# pmac_rx_secure register map
Vendor: Texas Instruments
Peripheral module from a debugger description file (folder CC35X1E).
Registers are 32-bit, read-only, reset 0x0 unless marked. A register's access mark holds for its fields unless they carry their own. Offsets are as the file gives them; lines under a group give offsets from that group; [hi:lo] are bit positions; {n}, {i} and the like mark numbered series; 'fields as' and 'values as' point back to an identical list; <NAME> marks a mode.

## pmac_rx_secure (part 1 of 3)
0x00 rx_reset access per field — Receive Reset (RX_RESET) Register
  [0] MEM_RXM_RESET rw — Receive Reset (rxm_reset) When set this bit puts the Receive Manager in reset.
0x04 sta_ssid0 rw — Station SSID Registers (STA_SSID0)
  [31:0] MEM_STA_SSID_031_000 — Station SSID bytes 3..0
0x08 sta_ssid1 rw — Station SSID Registers (STA_SSID1)
  [31:0] MEM_STA_SSID_063_032 — Station SSID bytes 7..4
0x0C sta_ssid2 rw — Station SSID Registers (STA_SSID2)
  [31:0] MEM_STA_SSID_095_064 — Station SSID bytes 11..8
0x10 sta_ssid3 rw — Station SSID Registers (STA_SSID3)
  [31:0] MEM_STA_SSID_127_096 — Station SSID bytes 15..12
0x14 sta_ssid4 rw — Station SSID Registers (STA_SSID4)
  [31:0] MEM_STA_SSID_159_128 — Station SSID bytes 23..20
0x18 sta_ssid5 rw — Station SSID Registers (STA_SSID5)
  [31:0] MEM_STA_SSID_191_160 — Station SSID bytes 23..20
0x1C sta_ssid6 rw — Station SSID Registers (STA_SSID6)
  [31:0] MEM_STA_SSID_223_192 — Station SSID bytes 27..24
0x20 sta_ssid7 rw — Station SSID Registers (STA_SSID7)
  [31:0] MEM_STA_SSID_255_224 — Station SSID bytes 31..28
0x24 ssid_len access per field — Station SSID Length (SSID_LEN)
  [5:0] MEM_SSID_LENGTH rw — Station SSID length in bytes. The number of valid bytes in STA_SSID0..7 to be used for comparison.
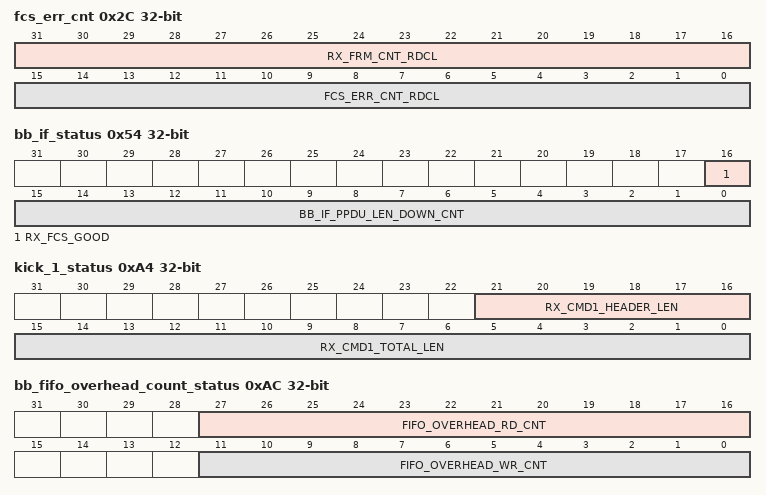
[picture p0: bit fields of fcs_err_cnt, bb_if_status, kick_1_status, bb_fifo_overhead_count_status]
0x2C fcs_err_cnt — Rx Frame count and FCS ERROR count
  [31:16] RX_FRM_CNT_RDCL — Counts number of MPDU_s received. does not count PLCP header errors clears on read
  [15:0] FCS_ERR_CNT_RDCL — Count of FCS errors detected by the Receive Manager. clears on read
0x30 rx_scrpt_tmp_mask access per field reset not defined
  [7:0] RX_SCRPT_TMP_MASK_IN_WROPT rw — used by the scripter on single address commands.
0x34 rx_scrpt_tmp_val access per field reset not defined
  [7:0] RX_SCRPT_TMP_VALUE_IN_WROPT rw — used by the scripter on specific commands and on if/jump commands
0x38 rx_scrpt_tmp_lnk access per field reset not defined
  [8:0] RX_SCRPT_TMP_LINK_IN_WROPT rw — used by the LINK command as the return address.
0x40 phy_hdr_word0
  [31:0] PHY_HEADER_WORD0 — [31:16] - Length [15:8] - Rate [7] - Aggregation (at 11n) [6] - Guard Interval (at 11n/11ac) 0x0: 0.4us (SGI) 0x1: 0.8us (LGI) [5:4] - BW (at 11n/ac/ax) [3:0] - Packet and Preamble type: 0x0: 11b short preamble 0x1: 11b long preamble 0x2: 11a/g (legacy OFDM) 0x3: 11n HT MF 0x4: 11ax SU 0x5: 11ax MU 0x6: 11ax SU ER 0x7: 11ax TB 0x8: 11ax TB non NDP 0x9: 11ac VHT 0xA-0xF: Reserved
0x44 phy_hdr_word1
  [31:0] PHY_HEADER_WORD1 — [31] - Reserved [30] - TXOP[6] (at 11ax) [29:24] - Group ID (at 11ac) / TXOP[5:0] (at 11ax) [23] - Reserved [22] - HT/VHT/HE error packet [21] - Legacy error packet [20:16] - Unsupported packet 0x0: Supported packet 0x1: LDPC coding 0x2: STBC 0x3: Rate 0x4: BW=40MHz 0x5: BW=80MHz 0x6: BW=160MHz 0x7: Greenfield preamble 0x8: MIMO 0x9: TB AX 0xA: VHT MU 0xB: HE Doppler 0xC: Other 0xD-0x1F: Reserved [15:14] - Reserved [13:8] - SNR [7:0] - RSSI
0x48 phy_hdr_word2
  [31:0] PHY_HEADER_WORD2 — [31:29] - GI & HE LTF Type (at 11ax) [28:16] - RX Time [15] - Uplink flag (at 11ax) [14:11] - Spacial reuse[3:0] (at 11ax) [10:9] - STA_ID_LIST[2:1] (at 11ax) [8] - Partial_AID[8] (at 11ac) / STA_ID_LIST[0] (at 11ax) [7:0] - Partial_AID[7:0] (at 11ac) / RU allocation (at 11ax)
0x4C phy_hdr_word3
  [31:0] PHY_HEADER_WORD3 — [31:16] - Reserved [15] - Beamformed [14] - DCM [13:8] - BSS color [7:0] - HE RSSI (at 11ax)
0x50 phy_mac_byte_cnt
  [19:0] PHY_MAC_BYTE_CNT — Register that monitors the number of bytes coming from the phy for each PPDU. Counter increments with "rxif_data_stb" and resets to "1" on "rxif_begin_stb"
0x54 bb_if_status
  [16] RX_FCS_GOOD — Indicates whether a received frame had a valid FCS
  [15:0] BB_IF_PPDU_LEN_DOWN_CNT — BB_IF PPDU Length down counter
{0x54+4i} mac_header_word{i} (i=1..9) — Receive MAC Header Registers (MAC_HEADER_WORD{i})
{0x54+4i} mac_header_word{i} (i=10..13) — Receive MAC Header Registers (MAC_HEADER_WORD9)
0x90 mac_header_bytecnt — Receive MAC Header Byte Count (MAC_HEADER_BYTECNT) Register
  [15:0] MAC_HEADER_BYTECNT — MAC Header Byte Count (mac_header_bytecnt). Number of valid bytes in the RX MAC HEADER registers.
0x94 fcs_word — Receive MAC Header Byte Count (MAC_HEADER_BYTECNT) Register
  [31:0] FCS_WORD — FCS word received from PHY
0xA0 rx_manager_ovrhd_word
  [31:0] RX_MNG_1ST_OVERHEAD_WORD — 1st overhead word that rx-manager reads from bb-fifo [15:0] = Frame Control [31:16] = MPDU-Length
0xA4 kick_1_status — status of last cmd1 (kick_1) from Rx-Manager to ENC (DMA)
  [21:16] RX_CMD1_HEADER_LEN — kick_1 MAC header length in bytes
  [15:0] RX_CMD1_TOTAL_LEN — kick_1 total_len in bytes without FCS
0xA8 mpdu_len_status
  [15:0] MPDU_LENGTH_BB_IF — MPDU length from BB_IF fifo input (including 4 bytes FCS) at first, when plcp rx_header received: loaded with PPDU_LENGTH in case of aggregation (AMPDU): loaded with MPDU_LEN from each head-delimiter
0xAC bb_fifo_overhead_count_status
  [27:16] FIFO_OVERHEAD_RD_CNT — number of overhead words read from bb-fifo (cleared at rx-header)
  [11:0] FIFO_OVERHEAD_WR_CNT — number of overhead words written to bb-fifo (cleared at rx-header)
0xB0 he_cfg access per field reset 0xFFF — Configuration for HE format
  [5:0] MEM_CFG_BSS_COLOR rw — Configurable 'BSS_COLOR' of this device.
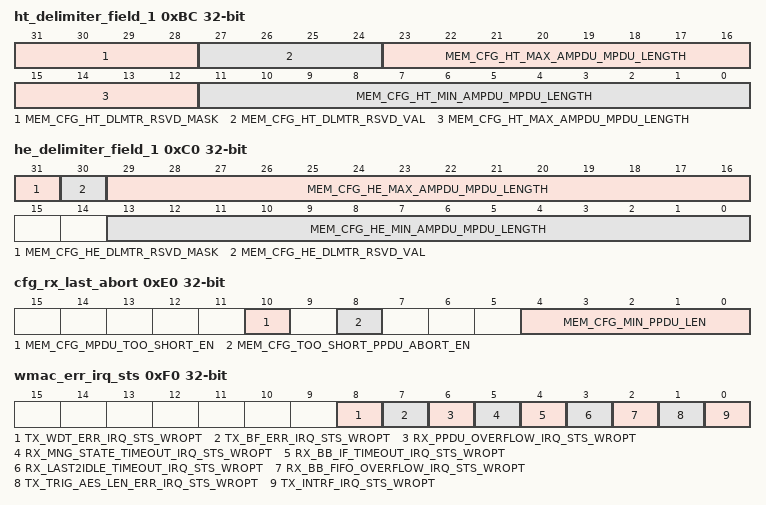
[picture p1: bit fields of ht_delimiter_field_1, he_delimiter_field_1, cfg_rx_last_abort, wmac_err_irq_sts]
0xBC ht_delimiter_field_1 rw reset not defined — contrls the configuration options of the AMPDU parsing for HT AMPDU 19xx name changed
  [31:28] MEM_CFG_HT_DLMTR_RSVD_MASK — 1 means that the related bit in delimiter reserved value field is not compared.
  [27:24] MEM_CFG_HT_DLMTR_RSVD_VAL — The reserved field of the delimiter is compared with this value (check mask feild below)
  [23:12] MEM_CFG_HT_MAX_AMPDU_MPDU_LENGTH — A delimiter with length bigger then the value in this feild is filterred.
  [11:0] MEM_CFG_HT_MIN_AMPDU_MPDU_LENGTH — A delimiter with length smaller then the value in this feild is filterred. min value is 14 = 10 (shortest MAC header) + 4 (FCS)
0xC0 he_delimiter_field_1 access per field reset not defined — contrls the configuration options of the AMPDU parsing for HE AMPDU
  [31] MEM_CFG_HE_DLMTR_RSVD_MASK rw — 1 means that the related bit in delimiter reserved value field is not compared.
  [30] MEM_CFG_HE_DLMTR_RSVD_VAL rw — The reserved field of the delimiter is compared with this value (check mask field below)
  [29:16] MEM_CFG_HE_MAX_AMPDU_MPDU_LENGTH rw — A delimiter with length bigger then the value in this feild is filterred.
  [13:0] MEM_CFG_HE_MIN_AMPDU_MPDU_LENGTH rw — A delimiter with length smaller then the value in this feild is filterred. min value is 14 = 10 (shortest MAC header) + 4 (FCS)
0xCC mac_abort access per field — Abort mac frame
  [0] MAC_ABORT_SW_CMD_WRCL wo — Create a pulse to abort current received frame
0xD0 cfg_abort_interrupt_mask access per field — Controls maskin the interrupts on RX path due to PPDU ABORT.
  [4:0] MEM_CFG_ABORT_INTERRUPT_MASK rw — [0] = cfg_mask_phy_termination [1] = cfg_mask_header_abort [2] = cfg_mask_suspend_req_to_phy [3] = cfg_mask_too_short_ppdu_abort [4] = cfg_mask_mac_abort
0xD4 abort_status access per field — This registers contains the status of the ppdu abort interrupt. The F/W should write 0 to clear this register bits.
  [4:0] PPDU_ABORT_STATUS_WROPT rw — [0] = phy_termination [1] = header_abort [2] = Abort due to suspend [3] = too_short_ppdu_abort [4] = mac_abort
0xD8 rx_spare_reg0 rw — spare register for future use
  [31:0] MEM_RX_SPARE_REG0
0xDC rx_spare_reg1 rw reset 0xFFFFFFFF — spare register for future use
  [31:0] MEM_RX_SPARE_REG1
0xE0 cfg_rx_last_abort access per field reset not defined — enable delay_last_abort feature which provied a last abort only after all but the aborted MPDU were analized thus preventing previous MPDUs from being aborted without a reason. WL9 new
  [10] MEM_CFG_MPDU_TOO_SHORT_EN rw — 1 - will set the byte_cnt to 63 to free scripter in case the mpdu is shorter than its mac header length and the scripter looks for a missing data 0 - feature disabled
  [8] MEM_CFG_TOO_SHORT_PPDU_ABORT_EN rw — 1- enable too_short_ppdu_abort i.e. ppdus less than a configured length that are not NDP will be aborted 0 - no abort on too short ppdu
  [4:0] MEM_CFG_MIN_PPDU_LEN rw — when cfg_too_short_ppdu_abort_en - a received ppdu with length under this number will be aborted
0xE4 cfg_ndp_fcs access per field reset 0x3 — enable setting fcs_ok for NDP packets to avoid EIFS timer start counting for NDP
  [0] MEM_CFG_NDP_IS_FCS_OK rw — "1" - NDP packets receiving outomatically sets the fcs_ok avoiding the EIFS timers from counting "0" - NDP packets are treated as having BAD FCS thus starting the EIFS timers counting.
0xF0 wmac_err_irq_sts access per field — pmac error indication status. This register allow clear - writing 1 will clear a source. Selective clear should be done with read-modify-write
  [8] TX_WDT_ERR_IRQ_STS_WROPT rw — unmasked irq status TX watchdog expiry.
  [7] TX_BF_ERR_IRQ_STS_WROPT rw — unmasked irq status. Beamforming NDPA was received with invalid parameters.
  [6] RX_PPDU_OVERFLOW_IRQ_STS_WROPT rw — unmasked irq status new PPDU received while previous not completed by rx-manager. PPDU processing is time is represented by RIP (rx in progress) set by rising of rx_header and cleared by rx_frm_stb which is rx_manager goes to IDLE after finished processing PPDU. PPDU_OVERFLOW is set if new rx_header is received while RIP is high
  [5] RX_MNG_STATE_TIMEOUT_IRQ_STS_WROPT rw — unmasked irq status rx_manager state (other than IDLE) is not changed for too long time time [msec] is defined in rx register MEM_RX_MNG_STATE_TIMEOUT_MSEC helps to identify if FSM is stuck
  [4] RX_BB_IF_TIMEOUT_IRQ_STS_WROPT rw — unmasked irq status RX BB I/F - no data received from phy for too long time checked from rx_header rise to rx_last time [usec] is defined in rx register MEM_BB_IF_TIMEOUT_USEC[5:0] helps to identify if MAC-PHY interface is stuck
  [3] RX_LAST2IDLE_TIMEOUT_IRQ_STS_WROPT rw — unmasked irq status IRQ generated if time elapsed from RX_LAST to RX_FRM_STB (manager-go-to-idle) is equal or above threshold. threshold is defined by rx-reg MEM_RX_STATISTICS_LAST2IDLE_THR[9:0] count in clock cycles (20MHz, 50ns) NOTE: part of RX_STATISTICS module, need to set mem_rx_statistics_en=1
  [2] RX_BB_FIFO_OVERFLOW_IRQ_STS_WROPT rw — unmasked irq status PHY try to write new data to RX BB FIFO while it is full (new data is lost)
  [1] TX_TRIG_AES_LEN_ERR_IRQ_STS_WROPT rw — unmasked irq status
  [0] TX_INTRF_IRQ_STS_WROPT rw — unmasked irq status
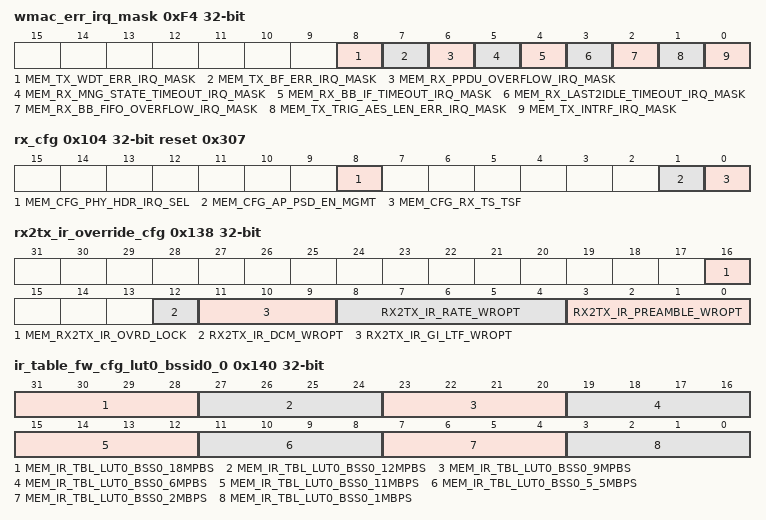
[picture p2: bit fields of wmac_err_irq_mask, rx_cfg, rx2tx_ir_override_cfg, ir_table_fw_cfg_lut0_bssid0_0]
0xF4 wmac_err_irq_mask access per field
  [8] MEM_TX_WDT_ERR_IRQ_MASK rw — when set, current source wont interrupt the SW. status will still be updated.
  [7] MEM_TX_BF_ERR_IRQ_MASK rw — when set, current source wont interrupt the SW. status will still be updated.
  [6] MEM_RX_PPDU_OVERFLOW_IRQ_MASK rw — when set, current source wont interrupt the SW. status will still be updated.
  [5] MEM_RX_MNG_STATE_TIMEOUT_IRQ_MASK rw — when set, current source wont interrupt the SW. status will still be updated.
  [4] MEM_RX_BB_IF_TIMEOUT_IRQ_MASK rw — when set, current source wont interrupt the SW. status will still be updated.
  [3] MEM_RX_LAST2IDLE_TIMEOUT_IRQ_MASK rw — when set, current source wont interrupt the SW. status will still be updated.
  [2] MEM_RX_BB_FIFO_OVERFLOW_IRQ_MASK rw — when set, current source wont interrupt the SW. status will still be updated.
  [1] MEM_TX_TRIG_AES_LEN_ERR_IRQ_MASK rw — when set, current source wont interrupt the SW. status will still be updated.
  [0] MEM_TX_INTRF_IRQ_MASK rw — when set, current source wont interrupt the SW. status will still be updated.
0x100 rx_timestamp — Receive Time Stamp (RX_TIMESTAMP)
  [31:0] RX_MAC_TIMESTAMP — Sample of timestamp counter (free running or TSF. see RX_CFG bit 0) on rx_header_stb
0x104 rx_cfg access per field reset 0x307 — HT managment is enabled
  [8] MEM_CFG_PHY_HDR_IRQ_SEL rw — Select location of phy-header interrupt: 0 - (default) at the end of phy_header (header fall) 1 - at the begining of phy_header (header rise)
  [1] MEM_CFG_AP_PSD_EN_MGMT rw — include management frame types when checking if a connected STA changed PS state. 1 - include mgmg 0 - only data frames.
  [0] MEM_CFG_RX_TS_TSF rw — Hardware Receive timestamp select (RX_TIMESTAMP); 0 = sample realtime free running microsecond counter; 1 = sample Access Manager TSF
0x10C cfg_ht_mgmt_en access per field reset 0x3 — HT managment is enabled
  [0] MEM_CFG_ENABLE_HT_MGMT rw — enable HT managment is enabled
0x138 rx2tx_ir_override_cfg access per field reset not defined
  [16] MEM_RX2TX_IR_OVRD_LOCK rw — Lock Override operation on rx2tx_ir_* outputs: 0 - Disable (Default) - Outputs override are valid only to this current frame, and will be released at the next frame start (phy_hdr_start_stb). 1 - Enable - When override (using this reg) - Output values are permanently lock for next frames, and can't be changed through HW.
  [12] RX2TX_IR_DCM_WROPT rw — 0 - DCM is not used (Default) 1 - Dual Carrier Modulation is used Note: DCM is only applied to MCS0, MCS1, MCS3 and MCS4
  [11:9] RX2TX_IR_GI_LTF_WROPT rw — In case og 11n/11ac: 0 - 0.4uS (SGI) 1 - 0.8uS (LGI) (Default) 2-7 - RESERVED ------------------------------- In case of 11ax: 0x0: 1xLTF+1.6us GI 0x1: 2xLTF+1.6us GI 0x2: 4xLTF+3.2us GI 0x3: 2xLTF+0.8us GI 0x4: 1xLTF+0.8us GI 0x5: 4xLTF+0.8us GI 0x6-0x7 - RESERVED
  [8:4] RX2TX_IR_RATE_WROPT rw — 5'h1 - 11B 1MBPS 5'h2 - 11B 2MBPS 5'h3 - 11B 5.5MBPS 5'h4 - 11B 11MBPS 5'h5 - 11AG 6MBPS (Default) 5'h6 - 11AG 9MBPS 5'h7 - 11AG 12MBPS 5'h8 - 11AG 18MBPS 5'h9 - 11AG 24MBPS 5'hA - 11AG 36MBPS 5'hB - 11AG 48MBPS 5'hC - 11AG 54MBPS 5'hD - 11N MCS0 //6.5 Mbps 5'hE - 11N MCS1 //13 Mbps 5'hF - 11N MCS2 //19.5 Mbps 5'h10 - 11N MCS3 //26 Mbps 5'h11 - 11N MCS4 //39 Mbps 5'h12 - 11N MCS5 //52 Mbps 5'h13 - 11N MCS6 //58.5 Mbps 5'h14 - 11N MCS7 //65 Mbps 5'h15 - 11N MCS7_SGI //72.2 Mbps
  [3:0] RX2TX_IR_PREAMBLE_WROPT rw — 0x0: 11b short preamble 0x1: 11b long preamble 0x2: 11a/g (legacy OFDM) (Default) 0x3: 11n HT Mixed-Mode 0x4: 11n GF 0x5: 11ax SU 0x6: 11ax MU 0x7: 11ax SU ER 0x8: 11ax TB (non NDP FB) 0x9: 11ax TB NDP TB 0xA: 11ac VHT 0xB: 11ax Unknown Type 0xC-0xF: Reserved
0x140 ir_table_fw_cfg_lut0_bssid0_0 rw — LUT0 - BSSID0 - for Legacy frame response. Configuration of the basic rate set of the BSSID (as published by the AP). Used to select the response rate for each input rate (legacy or translated-MCS rate to the closest legacy rate). * DANGEROUS - set with caution: * If you config response with 11B rate-1, and we receive 11B Short preamble, * we trigger imm-resp with INCOMPATIBLE params
  [31:28] MEM_IR_TBL_LUT0_BSS0_18MPBS — Configured RATE of the response frame for 18Mbps input rate (11a/g).
  [27:24] MEM_IR_TBL_LUT0_BSS0_12MPBS — Configured RATE of the response frame for 12Mbps input rate (11a/g).
  [23:20] MEM_IR_TBL_LUT0_BSS0_9MPBS — Configured RATE of the response frame for 9Mbps input rate (11a/g).
  [19:16] MEM_IR_TBL_LUT0_BSS0_6MPBS — Configured RATE of the response frame for 6Mbps input rate (11a/g).
  [15:12] MEM_IR_TBL_LUT0_BSS0_11MBPS — Configured RATE of the response frame for 11Mbps input rate (11b).
  [11:8] MEM_IR_TBL_LUT0_BSS0_5_5MBPS — Configured RATE of the response frame for 5.5Mbps input rate (11b).
  [7:4] MEM_IR_TBL_LUT0_BSS0_2MBPS — Configured RATE of the response frame for 2Mbps input rate (11b).
  [3:0] MEM_IR_TBL_LUT0_BSS0_1MBPS — Configured RATE of the response frame for 1Mbps input rate (11b).
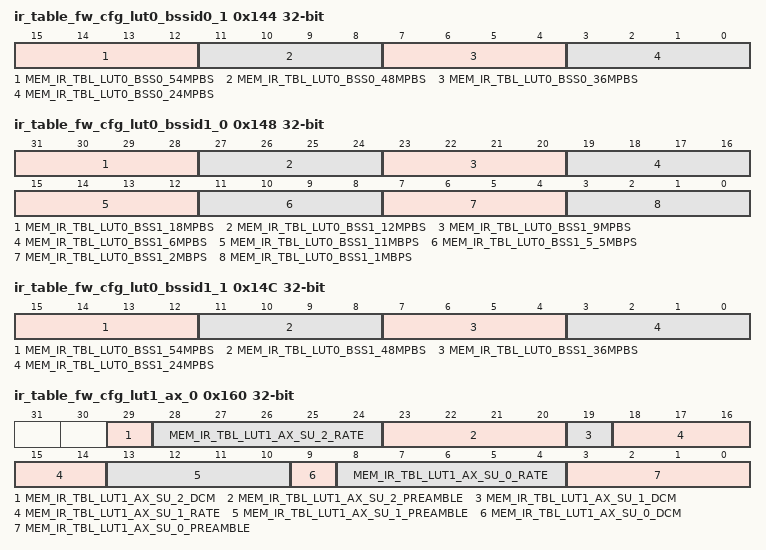
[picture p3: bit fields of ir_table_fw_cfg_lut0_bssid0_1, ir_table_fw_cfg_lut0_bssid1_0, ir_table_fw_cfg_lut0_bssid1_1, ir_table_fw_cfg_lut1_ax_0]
0x144 ir_table_fw_cfg_lut0_bssid0_1 access per field — LUT0 - BSSID0 - for Legacy frame response. Configuration of the basic rate set of the BSSID (as published by the AP). Used to select the response rate for each input rate (legacy or translated MCS-rate to the closest legacy rate).
  [15:12] MEM_IR_TBL_LUT0_BSS0_54MPBS rw — Configured RATE of the response frame for 54Mbps input rate (11a/g).
  [11:8] MEM_IR_TBL_LUT0_BSS0_48MPBS rw — Configured RATE of the response frame for 48Mbps input rate (11a/g).
  [7:4] MEM_IR_TBL_LUT0_BSS0_36MPBS rw — Configured RATE of the response frame for 36Mbps input rate (11a/g).
  [3:0] MEM_IR_TBL_LUT0_BSS0_24MPBS rw — Configured RATE of the response frame for 24Mbps input rate (11a/g).
0x148 ir_table_fw_cfg_lut0_bssid1_0 rw — LUT0 - BSSID1 - for Legacy frame response. Configuration of the basic rate set of the BSSID (as published by the AP). Used to select the response rate for each input rate (legacy or translated-MCS rate to the closest legacy rate). * DANGEROUS - set with caution: * If you config response with 11B rate-1, and we receive 11B Short preamble, * we trigger imm-resp with INCOMPATIBLE params
  [31:28] MEM_IR_TBL_LUT0_BSS1_18MPBS — Configured RATE of the response frame for 18Mbps input rate (11a/g).
  [27:24] MEM_IR_TBL_LUT0_BSS1_12MPBS — Configured RATE of the response frame for 12Mbps input rate (11a/g).
  [23:20] MEM_IR_TBL_LUT0_BSS1_9MPBS — Configured RATE of the response frame for 9Mbps input rate (11a/g).
  [19:16] MEM_IR_TBL_LUT0_BSS1_6MPBS — Configured RATE of the response frame for 6Mbps input rate (11a/g).
  [15:12] MEM_IR_TBL_LUT0_BSS1_11MBPS — Configured RATE of the response frame for 11Mbps input rate (11b).
  [11:8] MEM_IR_TBL_LUT0_BSS1_5_5MBPS — Configured RATE of the response frame for 5.5Mbps input rate (11b).
  [7:4] MEM_IR_TBL_LUT0_BSS1_2MBPS — Configured RATE of the response frame for 2Mbps input rate (11b).
  [3:0] MEM_IR_TBL_LUT0_BSS1_1MBPS — Configured RATE of the response frame for 1Mbps input rate (11b).
0x14C ir_table_fw_cfg_lut0_bssid1_1 access per field — LUT0 - BSSID1 - for Legacy frame response. Configuration of the basic rate set of the BSSID (as published by the AP). Used to select the response rate for each input rate (legacy or translated MCS-rate to the closest legacy rate).
  [15:12] MEM_IR_TBL_LUT0_BSS1_54MPBS rw — Configured RATE of the response frame for 54Mbps input rate (11a/g).
  [11:8] MEM_IR_TBL_LUT0_BSS1_48MPBS rw — Configured RATE of the response frame for 48Mbps input rate (11a/g).
  [7:4] MEM_IR_TBL_LUT0_BSS1_36MPBS rw — Configured RATE of the response frame for 36Mbps input rate (11a/g).
  [3:0] MEM_IR_TBL_LUT0_BSS1_24MPBS rw — Configured RATE of the response frame for 24Mbps input rate (11a/g).
0x160 ir_table_fw_cfg_lut1_ax_0 access per field — LUT1 - AX - for HE frame response. Configuration for the HE imm-resp Output set (Preamble, Rate, DCM). Param in: AX-SU (MCS0-MCS2)
  [29] MEM_IR_TBL_LUT1_AX_SU_2_DCM rw — Configured DCM mode of the AX response frame for MCS2 (19.5Mbps).
  [28:24] MEM_IR_TBL_LUT1_AX_SU_2_RATE rw — Configured RATE of the AX response frame for MCS2 (19.5Mbps).
  [23:20] MEM_IR_TBL_LUT1_AX_SU_2_PREAMBLE rw — Configured PREAMBLE of the AX response frame for MCS2 (19.5Mbps).
  [19] MEM_IR_TBL_LUT1_AX_SU_1_DCM rw — Configured DCM mode of the AX response frame for MCS1 (13Mbps).
  [18:14] MEM_IR_TBL_LUT1_AX_SU_1_RATE rw — Configured RATE of the AX response frame for MCS1 (13Mbps).
  [13:10] MEM_IR_TBL_LUT1_AX_SU_1_PREAMBLE rw — Configured PREAMBLE of the AX response frame for MCS1 (13Mbps).
  [9] MEM_IR_TBL_LUT1_AX_SU_0_DCM rw — Configured DCM mode of the AX response frame for MCS0 (6.5Mbps).
  [8:4] MEM_IR_TBL_LUT1_AX_SU_0_RATE rw — Configured RATE of the AX response frame for MCS0 (6.5Mbps).
  [3:0] MEM_IR_TBL_LUT1_AX_SU_0_PREAMBLE rw — Configured PREAMBLE of the AX response frame for MCS0 (6.5Mbps).
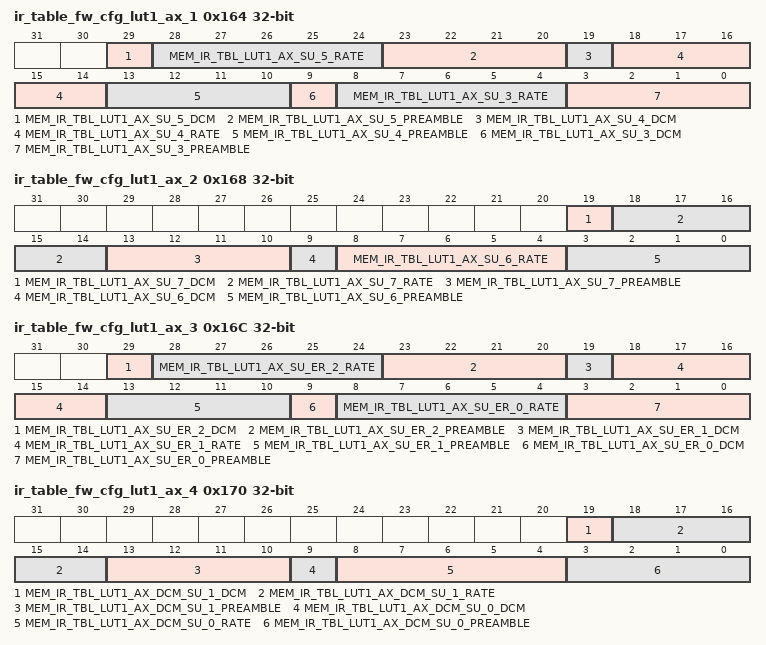
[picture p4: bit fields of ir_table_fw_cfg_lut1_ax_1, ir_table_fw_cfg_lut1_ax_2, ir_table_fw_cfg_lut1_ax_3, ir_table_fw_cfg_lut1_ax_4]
0x164 ir_table_fw_cfg_lut1_ax_1 access per field reset not defined — LUT1 - AX - for HE frame response. Configuration for the HE imm-resp Output set (Preamble, Rate, DCM). Param in: AX-SU (MCS2-MCS5)
  [29] MEM_IR_TBL_LUT1_AX_SU_5_DCM rw — Configured DCM mode of the AX response frame for MCS5 (52Mbps).
  [28:24] MEM_IR_TBL_LUT1_AX_SU_5_RATE rw — Configured RATE of the AX response frame for MCS5 (52Mbps).
  [23:20] MEM_IR_TBL_LUT1_AX_SU_5_PREAMBLE rw — Configured PREAMBLE of the AX response frame for MCS5 (52Mbps).
  [19] MEM_IR_TBL_LUT1_AX_SU_4_DCM rw — Configured DCM mode of the AX response frame for MCS4 (39Mbps).
  [18:14] MEM_IR_TBL_LUT1_AX_SU_4_RATE rw — Configured RATE of the AX response frame for MCS4 (39Mbps).
  [13:10] MEM_IR_TBL_LUT1_AX_SU_4_PREAMBLE rw — Configured PREAMBLE of the AX response frame for MCS4 (39Mbps).
  [9] MEM_IR_TBL_LUT1_AX_SU_3_DCM rw — Configured DCM mode of the AX response frame for MCS3 (26Mbps).
  [8:4] MEM_IR_TBL_LUT1_AX_SU_3_RATE rw — Configured RATE of the AX response frame for MCS3 (26Mbps).
  [3:0] MEM_IR_TBL_LUT1_AX_SU_3_PREAMBLE rw — Configured PREAMBLE of the AX response frame for MCS3 (26Mbps).
0x168 ir_table_fw_cfg_lut1_ax_2 access per field reset not defined — LUT1 - AX - for HE frame response. Configuration for the HE imm-resp Output set (Preamble, Rate, DCM). Param in: AX-SU (MCS6-MCS7)
  [19] MEM_IR_TBL_LUT1_AX_SU_7_DCM rw — Configured DCM mode of the AX response frame for MCS7 (72.2Mbps).
  [18:14] MEM_IR_TBL_LUT1_AX_SU_7_RATE rw — Configured RATE of the AX response frame for MCS7 (72.2Mbps).
  [13:10] MEM_IR_TBL_LUT1_AX_SU_7_PREAMBLE rw — Configured PREAMBLE of the AX response frame for MCS7 (72.2Mbps).
  [9] MEM_IR_TBL_LUT1_AX_SU_6_DCM rw — Configured DCM mode of the AX response frame for MCS6 (58.5Mbps).
  [8:4] MEM_IR_TBL_LUT1_AX_SU_6_RATE rw — Configured RATE of the AX response frame for MCS6 (58.5Mbps).
  [3:0] MEM_IR_TBL_LUT1_AX_SU_6_PREAMBLE rw — Configured PREAMBLE of the AX response frame for MCS6 (58.5Mbps).
0x16C ir_table_fw_cfg_lut1_ax_3 access per field reset not defined — LUT1 - AX - for HE frame response. Configuration for the HE imm-resp Output set (Preamble, Rate, DCM). Param in: AX-SU_ER (MCS0-MCS2)
  [29] MEM_IR_TBL_LUT1_AX_SU_ER_2_DCM rw — Configured DCM mode of the AX response frame for MCS2 (19.5Mbps).
  [28:24] MEM_IR_TBL_LUT1_AX_SU_ER_2_RATE rw — Configured RATE of the AX response frame for MCS2 (19.5Mbps).
  [23:20] MEM_IR_TBL_LUT1_AX_SU_ER_2_PREAMBLE rw — Configured PREAMBLE of the AX response frame for MCS2 (19.5Mbps).
  [19] MEM_IR_TBL_LUT1_AX_SU_ER_1_DCM rw — Configured DCM mode of the AX response frame for MCS1 (13Mbps).
  [18:14] MEM_IR_TBL_LUT1_AX_SU_ER_1_RATE rw — Configured RATE of the AX response frame for MCS1 (13Mbps).
  [13:10] MEM_IR_TBL_LUT1_AX_SU_ER_1_PREAMBLE rw — Configured PREAMBLE of the AX response frame for MCS1 (13Mbps).
  [9] MEM_IR_TBL_LUT1_AX_SU_ER_0_DCM rw — Configured DCM mode of the AX response frame for MCS0 (6.5Mbps).
  [8:4] MEM_IR_TBL_LUT1_AX_SU_ER_0_RATE rw — Configured RATE of the AX response frame for MCS0 (6.5Mbps).
  [3:0] MEM_IR_TBL_LUT1_AX_SU_ER_0_PREAMBLE rw — Configured PREAMBLE of the AX response frame for MCS0 (6.5Mbps).
0x170 ir_table_fw_cfg_lut1_ax_4 access per field reset not defined — LUT1 - AX - for HE frame response. Configuration for the HE imm-resp Output set (Preamble, Rate, DCM). Param in: AX-SU-DCM (MCS0-MCS2)
  [19] MEM_IR_TBL_LUT1_AX_DCM_SU_1_DCM rw — Configured DCM mode of the AX response frame for MCS1 (13Mbps).
  [18:14] MEM_IR_TBL_LUT1_AX_DCM_SU_1_RATE rw — Configured RATE of the AX response frame for MCS1 (13Mbps).
  [13:10] MEM_IR_TBL_LUT1_AX_DCM_SU_1_PREAMBLE rw — Configured PREAMBLE of the AX response frame for MCS1 (13Mbps).
  [9] MEM_IR_TBL_LUT1_AX_DCM_SU_0_DCM rw — Configured DCM mode of the AX response frame for MCS0 (6.5Mbps).
  [8:4] MEM_IR_TBL_LUT1_AX_DCM_SU_0_RATE rw — Configured RATE of the AX response frame for MCS0 (6.5Mbps).
  [3:0] MEM_IR_TBL_LUT1_AX_DCM_SU_0_PREAMBLE rw — Configured PREAMBLE of the AX response frame for MCS0 (6.5Mbps).
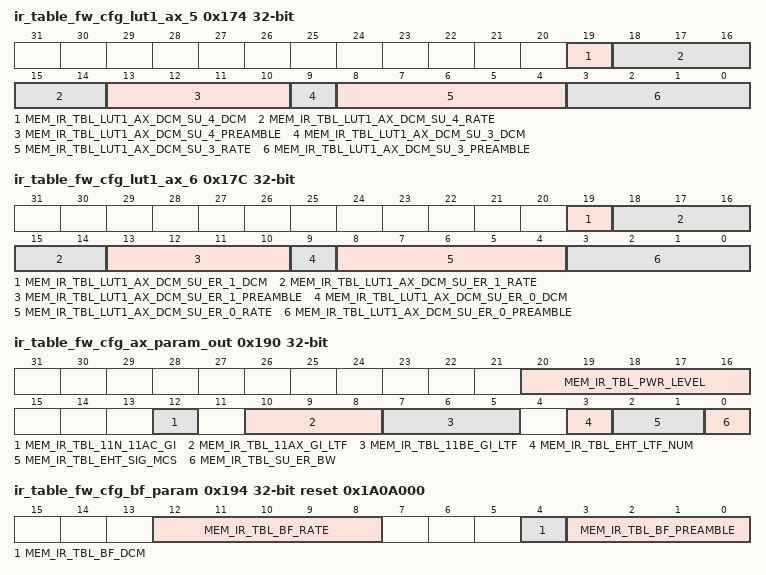
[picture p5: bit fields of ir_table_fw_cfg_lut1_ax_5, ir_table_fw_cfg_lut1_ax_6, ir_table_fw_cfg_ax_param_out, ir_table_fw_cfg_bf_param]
0x174 ir_table_fw_cfg_lut1_ax_5 access per field reset not defined — LUT1 - AX - for HE frame response. Configuration for the HE imm-resp Output set (Preamble, Rate, DCM). Param in: AX-SU-DCM (MCS2-MCS5)
  [19] MEM_IR_TBL_LUT1_AX_DCM_SU_4_DCM rw — Configured DCM mode of the AX response frame for MCS4 (39Mbps).
  [18:14] MEM_IR_TBL_LUT1_AX_DCM_SU_4_RATE rw — Configured RATE of the AX response frame for MCS4 (39Mbps).
  [13:10] MEM_IR_TBL_LUT1_AX_DCM_SU_4_PREAMBLE rw — Configured PREAMBLE of the AX response frame for MCS4 (39Mbps).
  [9] MEM_IR_TBL_LUT1_AX_DCM_SU_3_DCM rw — Configured DCM mode of the AX response frame for MCS3 (26Mbps).
  [8:4] MEM_IR_TBL_LUT1_AX_DCM_SU_3_RATE rw — Configured RATE of the AX response frame for MCS3 (26Mbps).
  [3:0] MEM_IR_TBL_LUT1_AX_DCM_SU_3_PREAMBLE rw — Configured PREAMBLE of the AX response frame for MCS3 (26Mbps).
0x17C ir_table_fw_cfg_lut1_ax_6 access per field reset not defined — LUT1 - AX - for HE frame response. Configuration for the HE imm-resp Output set (Preamble, Rate, DCM). Param in: AX-SU_ER-DCM (MCS0-MCS2)
  [19] MEM_IR_TBL_LUT1_AX_DCM_SU_ER_1_DCM rw — Configured DCM mode of the AX response frame for MCS1 (13Mbps).
  [18:14] MEM_IR_TBL_LUT1_AX_DCM_SU_ER_1_RATE rw — Configured RATE of the AX response frame for MCS1 (13Mbps).
  [13:10] MEM_IR_TBL_LUT1_AX_DCM_SU_ER_1_PREAMBLE rw — Configured PREAMBLE of the AX response frame for MCS1 (13Mbps).
  [9] MEM_IR_TBL_LUT1_AX_DCM_SU_ER_0_DCM rw — Configured DCM mode of the AX response frame for MCS0 (6.5Mbps).
  [8:4] MEM_IR_TBL_LUT1_AX_DCM_SU_ER_0_RATE rw — Configured RATE of the AX response frame for MCS0 (6.5Mbps).
  [3:0] MEM_IR_TBL_LUT1_AX_DCM_SU_ER_0_PREAMBLE rw — Configured PREAMBLE of the AX response frame for MCS0 (6.5Mbps).
0x190 ir_table_fw_cfg_ax_param_out access per field reset not defined — AX parameters - for HE frame response. Configuration for the HE imm-resp Output set: SU_ER_BW, GI_LTF PWR_LEVEL.
  [20:16] MEM_IR_TBL_PWR_LEVEL rw — Power Level selection for imm response. (Statically configuration - Not related to the frame params in) Configured HE single user (SU), HE extended range (ER) of the AX response frame. (Statically configuration - Not related to the frame params in)
  [12] MEM_IR_TBL_11N_11AC_GI rw — Configured GI subfield of the 11N/11AC response frame. (Statically configuration - Not related to the frame params in) 0 - 0.4uS (SGI) 1 - 0.8uS (LGI) (Default)
  [10:8] MEM_IR_TBL_11AX_GI_LTF rw — Configured GI and LTF Type subfield of the AX response frame. (Statically configuration - Not related to the frame params in) 0x0: 1xLTF+1.6us GI 0x1: 2xLTF+1.6us GI 0x2: 4xLTF+3.2us GI (Default) 0x3: 2xLTF+0.8us GI 0x4: 1xLTF+0.8us GI 0x5: 4xLTF+0.8us GI 0x6-0x7 - RESERVED
  [7:5] MEM_IR_TBL_11BE_GI_LTF rw — Configured GI and LTF Type subfield of the BE response frame. (Statically configuration - Not related to the frame params in) 0x0: 1xLTF+1.6us GI 0x1: 2xLTF+1.6us GI 0x2: 4xLTF+3.2us GI (Default) 0x3: 2xLTF+0.8us GI 0x4: 1xLTF+0.8us GI 0x5: 4xLTF+0.8us GI 0x6-0x7 - RESERVED
  [3] MEM_IR_TBL_EHT_LTF_NUM rw — Configured HE single user (SU), HE extended range (ER) of the AX response frame. (Statically configuration - Not related to the frame params in)
  [2:1] MEM_IR_TBL_EHT_SIG_MCS rw — Configured HE single user (SU), HE extended range (ER) of the AX response frame. (Statically configuration - Not related to the frame params in)
  [0] MEM_IR_TBL_SU_ER_BW rw — Configured HE single user (SU), HE extended range (ER) of the AX response frame. (Statically configuration - Not related to the frame params in)
0x194 ir_table_fw_cfg_bf_param access per field reset 0x1A0A000 (reset mask 0xFFFFE000) — Dedicated parameters - for BeamForming frame. Configuration Output set: PREAMBLE RATE
  [12:8] MEM_IR_TBL_BF_RATE rw — Configured RATE for BeamForming frame transmission.
  [4] MEM_IR_TBL_BF_DCM rw — Configured DCM for BeamForming frame transmission.
  [3:0] MEM_IR_TBL_BF_PREAMBLE rw — Configured PREAMBLE for BeamForming frame transmission.
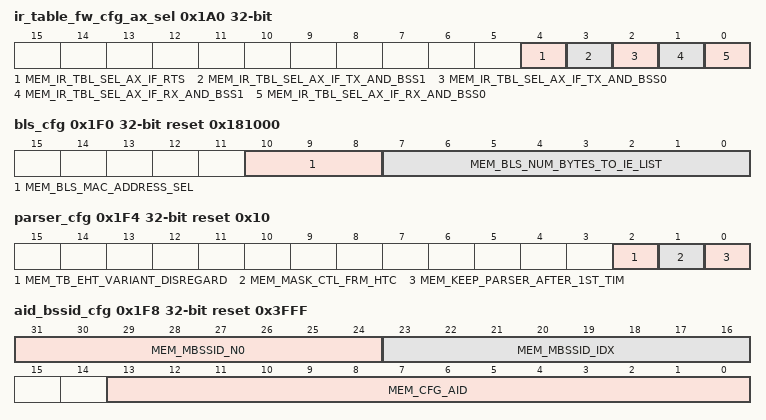
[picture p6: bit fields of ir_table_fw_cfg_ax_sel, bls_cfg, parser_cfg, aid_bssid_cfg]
0x1A0 ir_table_fw_cfg_ax_sel access per field — Configuration bits for the decision of selecting AX Table (LUT1) over the Legacy one (LUT0)
  [4] MEM_IR_TBL_SEL_AX_IF_RTS rw — Select AX Table if: Frame Type: Control-RTS
  [3] MEM_IR_TBL_SEL_AX_IF_TX_AND_BSS1 rw — Select AX Table if: 1. Client = PMAC-TX 2. BSSID Role Index = 1
  [2] MEM_IR_TBL_SEL_AX_IF_TX_AND_BSS0 rw — Select AX Table if: 1. Client = PMAC-TX 2. BSSID Role Index = 0
  [1] MEM_IR_TBL_SEL_AX_IF_RX_AND_BSS1 rw — Select AX Table if: 1. Client = PMAC-RX 2. BSSID Role Index = 1
  [0] MEM_IR_TBL_SEL_AX_IF_RX_AND_BSS0 rw — Select AX Table if: 1. Client = PMAC-RX 2. BSSID Role Index = 0
0x1F0 bls_cfg access per field reset 0x181000 (reset mask 0xFFFFF800) — BLS feature configuration
  [10:8] MEM_BLS_MAC_ADDRESS_SEL rw — Select one of the 6 configurable MAC-Addresses (ADDR_SRCH_ADDR_*) to the fake SA (address 2) of the BLS frame. This way it gets valid link/role/bssid matches and indexs
  [7:0] MEM_BLS_NUM_BYTES_TO_IE_LIST rw — Configuration of the number of bytes, after the sync pattern, and before start of new IE. Constrains on this value: * Must be >=2 (since it is used also as 'hdr_len', so can't be 0) * In range of [2..24] must be even number, otherwise any value
0x1F4 parser_cfg access per field reset 0x10 (reset mask 0xFFFFFFF8)
  [2] MEM_TB_EHT_VARIANT_DISREGARD rw — When set, parser will treat all tb frames as HE regardless of actual format
  [1] MEM_MASK_CTL_FRM_HTC rw — Mask HTC bit (frame control bit-15) in case AP uses it as reserved and sends control frame with 'HTC=1' and without HT-Control field.
  [0] MEM_KEEP_PARSER_AFTER_1ST_TIM rw — In case there are several TIM-Elements in a frame: 0 - (default) - stop searching for Broadcast/Unicast indication after 1st TIM. 1 - keep searching and parsing till the end of packet.
0x1F8 aid_bssid_cfg access per field reset 0x3FFF (reset mask 0x3FFF) — Association ID Register + Multi BSSID configuration
  [31:24] MEM_MBSSID_N0 rw — For Single-BSSID (n=0): Set N0 to 0. For Multi-BSSID: For n={1,2,3,4,5,6,7...} - N0 should be set to {1,1,1,2,4,8,16...} respectively. (n - is an integer power of 2, where n^2 is the maximum possible number of BSSID; and N0 is the smallest positive integer such that: N0 x 8 - 2^n < 8) In case of Multi BSSID mode, this register value (=N0) helps to extract the traffic indication bit of the associated station from the virtual bitmap of the TIM element: If Bitmap Offset = 0, N0 is don't care and traffic indication virtual bitmap is extracted according to method A, (BBSID's broadcast indication is according to mbssid_idx reg). If Bitmap Offset > 0, Using it + N0 to find AID_min in the virtual bitmap - according to Method B.
  [23:16] MEM_MBSSID_IDX rw — This register value is the index of actually supported BSSID, where the corresponding bit in the vbm indicates on broadcast frames that are buffered at the AP for this BSS: In case of multi BSSID mode: 'mbssid_idx' can be in range of [0:k] (where k<=(2^n - 1), 'mbssid_idx'=0 corresponds to the transmitted BSSID, and 'mssid_idx'>0 to one of the non-transmitted BSSID). In case of single BSSID mode: This register value is don't-care.
  [13:0] MEM_CFG_AID rw — AID of station
{0x1F8+8i} parser_rx_addr_{i}_lsb (i=1..4)
  [31:0] RX_ADDR{i}_31_00 — Note: bits [7:0] are actually ADDR MSB = first byte from air
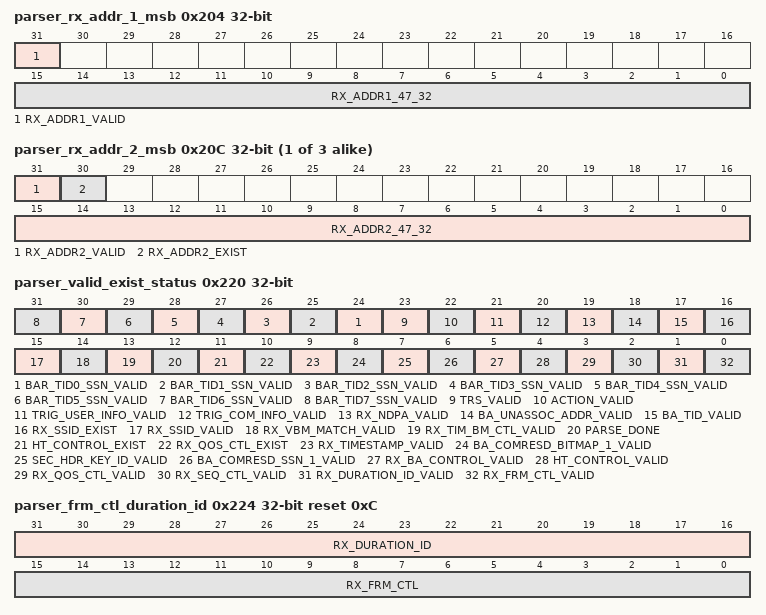
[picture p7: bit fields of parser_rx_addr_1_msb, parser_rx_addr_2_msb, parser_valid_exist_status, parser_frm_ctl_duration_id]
0x204 parser_rx_addr_1_msb
  [31] RX_ADDR1_VALID
  [15:0] RX_ADDR1_47_32 — Note: reg bits [15:8] = ADDR[47:40] are actually ADDR LSB = last byte from air
{0x1FC+8i} parser_rx_addr_{i}_msb (i=2..4)
  [31] RX_ADDR{i}_VALID
  [30] RX_ADDR{i}_EXIST
  [15:0] RX_ADDR{i}_47_32 — Note: reg bits [15:8] = ADDR[47:40] are actually ADDR LSB = last byte from air
0x220 parser_valid_exist_status
  [n+24] BAR_TID{n}_SSN_VALID (n=0..7), [23] TRS_VALID, [22] ACTION_VALID, [21] TRIG_USER_INFO_VALID, [20] TRIG_COM_INFO_VALID, [19] RX_NDPA_VALID, [18] BA_UNASSOC_ADDR_VALID, [17] BA_TID_VALID, [16] RX_SSID_EXIST, [15] RX_SSID_VALID, [14] RX_VBM_MATCH_VALID, [13] RX_TIM_BM_CTL_VALID, [12] PARSE_DONE, [11] HT_CONTROL_EXIST, [10] RX_QOS_CTL_EXIST, [9] RX_TIMESTAMP_VALID, [8] BA_COMRESD_BITMAP_1_VALID, [7] SEC_HDR_KEY_ID_VALID, [6] BA_COMRESD_SSN_1_VALID, [5] RX_BA_CONTROL_VALID, [4] HT_CONTROL_VALID, [3] RX_QOS_CTL_VALID, [2] RX_SEQ_CTL_VALID, [1] RX_DURATION_ID_VALID, [0] RX_FRM_CTL_VALID
0x224 parser_frm_ctl_duration_id reset 0xC
  [31:16] RX_DURATION_ID, [15:0] RX_FRM_CTL
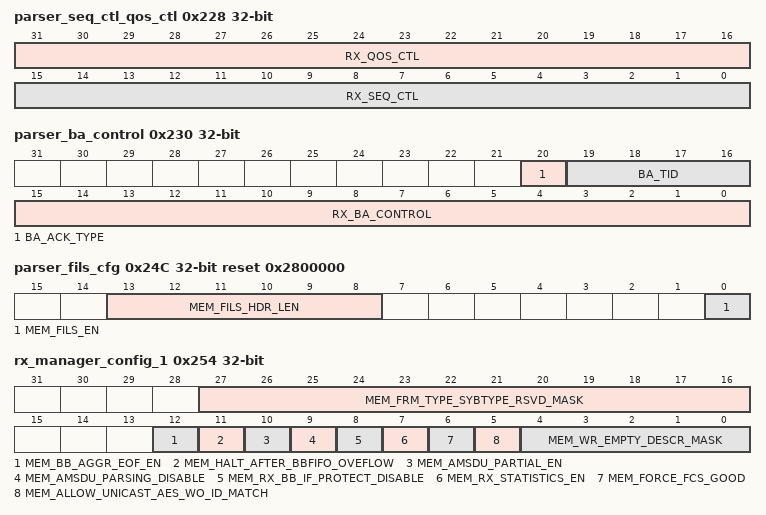
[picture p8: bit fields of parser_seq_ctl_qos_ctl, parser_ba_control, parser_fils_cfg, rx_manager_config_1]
0x228 parser_seq_ctl_qos_ctl
  [31:16] RX_QOS_CTL, [15:0] RX_SEQ_CTL
0x22C parser_ht_control
  [31:0] HT_CONTROL
0x230 parser_ba_control
  [20] BA_ACK_TYPE, [19:16] BA_TID, [15:0] RX_BA_CONTROL
0x234 parser_ba_comresd_ssn_1
  [15:0] BA_COMRESD_SSN_1
0x238 parser_ba_comresd_bitmap_1_lsb
  [31:0] BA_COMRESD_BITMAP_1_31_00
0x23C parser_ba_comresd_bitmap_1_msb
  [31:0] BA_COMRESD_BITMAP_1_63_32
0x240 parser_rx_timestamp_lsb
  [31:0] RX_TIMESTAMP_31_00
0x244 parser_rx_timestamp_msb
  [31:0] RX_TIMESTAMP_63_32
0x24C parser_fils_cfg access per field reset 0x2800000 (reset mask 0xFFFFC000) — configurations for FILS discovery action frame reception (11ax)
  [13:8] MEM_FILS_HDR_LEN rw — Set the header length for FILS descovery action frame. The header length includes the action field and the information field
  [0] MEM_FILS_EN rw — Enable reception of FILS discovery action frame. If this bit is set to one the user must also configure the MEM_FILS_HDR_LEN register.
0x250 rx_mng_early_trg_base_stat
  [0] WSOC_RX_TRIGGER_FRAME_IND — Trigger-Early-Indication to PHY. Set at TRS or TB-Base Clear at TX header, or SIFS counter ends (in case there is no TX)
0x254 rx_manager_config_1 access per field reset not defined — override the "fcs_good" bit from BB-FIFO output for each MPDU
  [27:16] MEM_FRM_TYPE_SYBTYPE_RSVD_MASK rw — mask bit for treating each type/subtype as reserved. relevant for RX_MANAGER decision to set "header_processiong_avoid" value: 0 - the type/subtype is reserved, go to "header_processiong_avoid" 1 - the type/subtype is not reserved, go on with normal flow bit mapping: [0] - type = management, subtype=0x7 [1] - type = management, subtype=0xF [2] - type = control, subtype=0x0 [3] - type = control, subtype=0x1 [4] - type = control, subtype=0x2 [5] - type = control, with protected bit set is forbidden [9] - type = reserved, type == 0x3 (FRM_T_EXT) [10] - protocol_version is not "00" [11] - control-wrapper frame (type=control, subtype=0x7) - TEMPORARY BUG FIX !!!
  [12] MEM_BB_AGGR_EOF_EN rw — In case of Aggregation format, there is end of frame indication (eof bit + length zero) which says there shouldn't be any more MPDU afterwards. This configuration bit will enable this indication (default='1') - and therefore: stops writing to FIFO, and sends this indication to Suspend module to enable suspending the rest of the Frame. If this bit is disabled ('0') - data will keep be writing to the FIFO, and no option to suspend the rest of the frame.
  [11] MEM_HALT_AFTER_BBFIFO_OVEFLOW rw — normally after BB_FIFO OVERFLOW the BB_IF stops writing to FIFO, and returns SCMDACCEPT to ENC until PPDU is finished. this behaviour enables recovery from overflow. for debug purpose only (FPGA) we want to stop the transactions after overflow, in order to keep all status registers from current PPDU and avoid overwrite with new PPDU values. setting this bit to '1' will stop the SCMDACCEPT from BB_IF to ENC, causing the entire PMAC_RX to halt
  [10] MEM_AMSDU_PARTIAL_EN rw — enable reception of AMSDU (join to rx-complete) even if one frame was dropped Note: if the first frame in AMSDU was dropped, the entire AMSDU will be dropped even if partial is enabled
  [9] MEM_AMSDU_PARSING_DISABLE rw — disable parsing of AMSDU (force is_amsdu=0)
  [8] MEM_RX_BB_IF_PROTECT_DISABLE rw — disable bb_if protect from new ppdu if currently ppdu processing is not finished
  [7] MEM_RX_STATISTICS_EN rw — clock-enable for rx_statistics counters
  [6] MEM_FORCE_FCS_GOOD rw
  [5] MEM_ALLOW_UNICAST_AES_WO_ID_MATCH rw — allow AES in unicast if no ID (index) match. id_match is between ID received from parser (sec_header) and ID copied from LINK_DB. in case is_protected=1 and is_unicast=1 but parser_id is not matched, need to decide how to operate ENC: 0 - use DMA mode and set id_mismatch=1 (error) 1 - use AES mode (decrypt) and ignore the id_mismatch
  [4:0] MEM_WR_EMPTY_DESCR_MASK rw — mask the write of empty descriptor for received phy frames with no data 0 - enable write of empty descriptor 1 - disable write of empty descriptor used by rx manager FSM bit per scenarrio: [4] - HT/VHT/HE SIG error [3] - plcp unsupported packet [2] - zero len plcp [1] - rx_last without any data strobe since rx_header [0] - plcp error packet NOTE: due to phy implementation, to successfully mask empty descr for unsupported frames, both bits 1 AND 3 should be 1! Same is true for err pkts - bits 0 and 1 should be 1
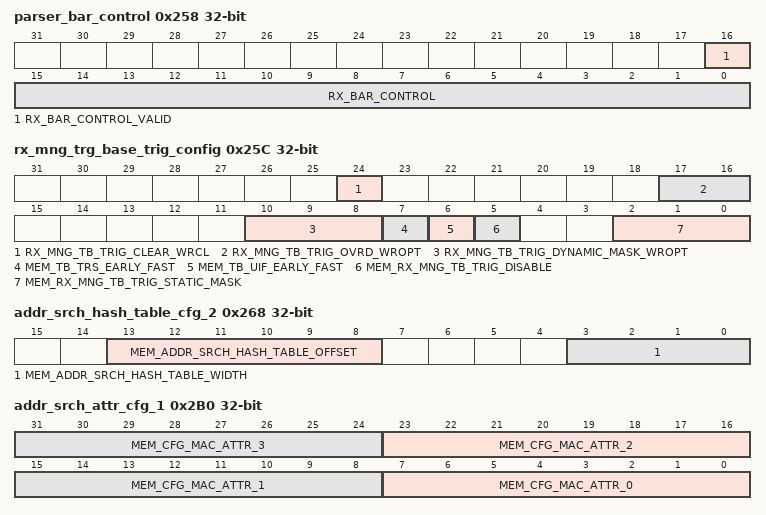
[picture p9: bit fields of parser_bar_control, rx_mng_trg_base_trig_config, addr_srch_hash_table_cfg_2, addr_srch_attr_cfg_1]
0x258 parser_bar_control
  [16] RX_BAR_CONTROL_VALID, [15:0] RX_BAR_CONTROL
0x25C rx_mng_trg_base_trig_config access per field
  [24] RX_MNG_TB_TRIG_CLEAR_WRCL wo — write of '1' to this bit will clear the immediate response trigger decision that was latched (before the override MUX)
  [17:16] RX_MNG_TB_TRIG_OVRD_WROPT rw — bit[0] = trigger base trigger override value: 0=no trigger ; 1=enable trigger bit[1] = trigger base trigger override select: 0=no override ; 1=override according to bit[0]
  [10:8] RX_MNG_TB_TRIG_DYNAMIC_MASK_WROPT rw — dynamic bit-mask for triger base response trigger. see STATIC for bit-mapping wropt - can be loaded by RX_SCR after new PPDU start
  [7] MEM_TB_TRS_EARLY_FAST rw — PHY Early indication for Trigger base due TRS: '1' - Send trigger base early indication to PHY as soon as parser match (get TRS with immediate response trigger set). '0' - Send trigger base early indication to PHY upon parset match AND FCS was goog AND scriptter done MPDU script AND Rx Last has been set.
  [6] MEM_TB_UIF_EARLY_FAST rw — PHY Early indication for Trigger base due to valid USER INFO: '1' - Send trigger base early indication to PHY as soon as parser match (get USER INFO VALID with either aid or oura match). '0' - Send trigger base early indication to PHY upon parset match AND FCS was goog AND scriptter done MPDU script AND Rx Last has been set.
  [5] MEM_RX_MNG_TB_TRIG_DISABLE rw — '1' - disable trigger base response trigger. static value, stronger than OVRD_WROPT register that is cleared at every PPDU start
  [2:0] MEM_RX_MNG_TB_TRIG_STATIC_MASK rw — static mask for trigger base response trigger, copied to dynamic mask by rx_manager at every new ppdu start. [0] = rx_fcs_good (mask=1 will generate TB as if FCS=good) [1] = rx_last_received (mask=1 will set TB before rx_last; DANGEROUS, set with caution) [2] = abort (mask=1 will allow TB after abort, at mask=0 TB will not be triggered at abort)
0x260 addr_srch_full_address_table access per field reset not defined
  [23:0] MEM_ADDR_SRCH_FULL_ADDRESS_TABLE rw
0x264 addr_srch_hash_table_cfg_1 access per field reset not defined
  [23:0] MEM_ADDR_SRCH_HASH_TABLE rw — Hash Table OCP Address
0x268 addr_srch_hash_table_cfg_2 access per field reset not defined
  [13:8] MEM_ADDR_SRCH_HASH_TABLE_OFFSET rw, [3:0] MEM_ADDR_SRCH_HASH_TABLE_WIDTH rw
{0x270+8i} addr_srch_addr_{i}_lsb rw reset not defined (i=0..5)
  [31:0] MEM_CFG_MAC_ADDRESS_{i}_31_00
{0x274+8i} addr_srch_addr_{i}_msb access per field reset not defined (i=0..5)
  [15:0] MEM_CFG_MAC_ADDRESS_{i}_47_32 rw
0x2B0 addr_srch_attr_cfg_1 rw
  [8n+7:8n] MEM_CFG_MAC_ATTR_{n} (n=0..3)
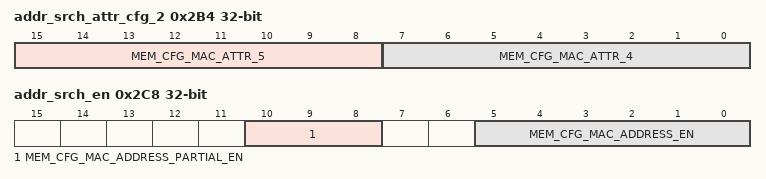
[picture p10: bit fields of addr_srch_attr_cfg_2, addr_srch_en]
0x2B4 addr_srch_attr_cfg_2 access per field
  [15:8] MEM_CFG_MAC_ATTR_5 rw, [7:0] MEM_CFG_MAC_ATTR_4 rw
0x2B8 addr_srch_addr_mask_0_lsb rw reset not defined
  [31:0] MEM_CFG_MAC_ADDRESS_MASK_0_31_00
0x2BC addr_srch_addr_mask_0_msb access per field reset not defined
  [15:0] MEM_CFG_MAC_ADDRESS_MASK_0_47_32 rw
0x2C0 addr_srch_addr_mask_1 access per field reset not defined
  [23:0] MEM_CFG_MAC_ADDRESS_MASK_1 rw
0x2C4 addr_srch_addr_mask_2 access per field reset not defined
  [23:0] MEM_CFG_MAC_ADDRESS_MASK_2 rw
0x2C8 addr_srch_en access per field reset not defined
  [10:8] MEM_CFG_MAC_ADDRESS_PARTIAL_EN rw — Enable bits for multiple BSSID match Bit[0] - Enable MAC address 0 partial match Bit[1] - Enable MAC address 1 partial match Bit[2] - Enable MAC address 2 partial match note that when SW updates the addr values in maskable registers (0-2), requirement is to write 0 to 'partial_en' as well as "global" enable ("mac_address_en") before changing value, and setting the partial_en once again when the address is written
  [5:0] MEM_CFG_MAC_ADDRESS_EN rw — Enable bits for MAC address complete match Bit[0] - Enable MAC address 0 complete match Bit[1] - Enable MAC address 1 complete match Bit[2] - Enable MAC address 2 complete match Bit[3] - Enable MAC address 3 complete match Bit[4] - Enable MAC address 4 complete match Bit[5] - Enable MAC address 5 complete match
0x2D0 addr_srch_addr4_cfg access per field reset not defined
  [0] MEM_CFG_ADDR4_SEARCH_EN rw — Allow address search state machine to process address 4
